# PIC32MZ0512EFF144 device description
Architecture: 32xxxx; Family: PIC32MZEF; Series: PIC32MZ
Registers are 32-bit, read-write, no defined reset value unless marked. A register's access mark holds for its fields unless they carry their own. Offsets are from the block's base; [hi:lo] are bit positions; {n}, {i} and the like mark numbered series; 'fields as' and 'values as' point back to an identical list.

## RPIN
Instances: RPIN 0x1f801404 in periph_pb1_std
0x00 INT1R
  [3:0] INT1R
0x04 INT2R
  [3:0] INT2R
0x08 INT3R
  [3:0] INT3R
0x0C INT4R
  [3:0] INT4R
{0xC+4i} T{i}CKR (i=2..9)
  [3:0] T{i}CKR
{0x30+4i} IC{i}R (i=1..9)
  [3:0] IC{i}R
0x5C OCFAR
  [3:0] OCFAR
{0x5C+8i} U{i}RXR (i=1..6)
  [3:0] U{i}RXR
{0x60+8i} U{i}CTSR (i=1..6)
  [3:0] U{i}CTSR
{0x8C+0xC*i} SDI{i}R (i=1..6)
  [3:0] SDI{i}R
{0x90+0xC*i} SS{i}R (i=1..6)
  [3:0] SS{i}R
0xDC C1RXR
  [3:0] C1RXR
0xE0 C2RXR
  [3:0] C2RXR
0xE4 REFCLKI1R
  [3:0] REFCLKI1R
0xEC REFCLKI3R
  [3:0] REFCLKI3R
0xF0 REFCLKI4R
  [3:0] REFCLKI4R

## RPOUT
Instances: RPOUT 0x1f801538 in periph_pb1_std
0x00 RPA14R
  [3:0] RPA14R
0x04 RPA15R
  [3:0] RPA15R
{0x8+4i} RPB{i}R (i=0..3)
  [3:0] RPB{i}R
{0x8+4i} RPB{i}R (i=5..10)
  [3:0] RPB{i}R
0x40 RPB14R
  [3:0] RPB14R
0x44 RPB15R
  [3:0] RPB15R
{0x48+4i} RPC{i}R (i=1..4)
  [3:0] RPC{i}R
0x7C RPC13R
  [3:0] RPC13R
0x80 RPC14R
  [3:0] RPC14R
{0x88+4i} RPD{i}R (i=0..7)
  [3:0] RPD{i}R
{0x88+4i} RPD{i}R (i=9..12)
  [3:0] RPD{i}R
0xC0 RPD14R
  [3:0] RPD14R
0xC4 RPD15R
  [3:0] RPD15R
0xD4 RPE3R
  [3:0] RPE3R
0xDC RPE5R
  [3:0] RPE5R
0xE8 RPE8R
  [3:0] RPE8R
0xEC RPE9R
  [3:0] RPE9R
{0x108+4i} RPF{i}R (i=0..5)
  [3:0] RPF{i}R
0x128 RPF8R
  [3:0] RPF8R
0x138 RPF12R
  [3:0] RPF12R
0x13C RPF13R
  [3:0] RPF13R
0x148 RPG0R
  [3:0] RPG0R
0x14C RPG1R
  [3:0] RPG1R
{0x148+4i} RPG{i}R (i=6..9)
  [3:0] RPG{i}R

## RTCC
Instances: RTCC 0x1f800c00 in periph_pb1_std
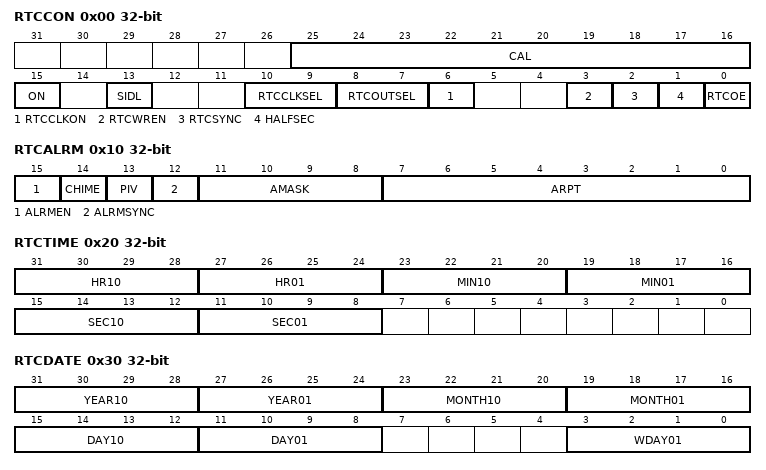
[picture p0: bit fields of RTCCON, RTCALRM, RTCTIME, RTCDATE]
0x00 RTCCON — Real-Time Clock and Calendar Control Register
  [25:16] CAL — Real-Time Clock Drift Calibration bits
    0x1ff=Maximum positive adjustment; 1=Minimum positive adjustment; 0=No adjustment; 0x3ff=Minimum negative adjustment; 0x200=Minimum negative adjustment
  [15] ON — RTCC On bit
    1=RTCC module is enabled; 0=RTCC module is disabled
  [13] SIDL — Stop in Idle Mode bit
    1=Disables RTCC operation when CPU enters Idle mode; 0=Continue normal operation when CPU enters Idle mode
  [10:9] RTCCLKSEL — RTCC Clock Select bits
    1=RTCC uses the external 32.768 kHz Secondary Oscillator (SOSC); 0=RTCC uses the internal 32 kHz oscillator (LPRC)
  [8:7] RTCOUTSEL — RTCC Output Data Select bits
    2=RTCC Clock is presented on the RTCC pin; 1=Seconds Clock is presented on the RTCC pin; 0=Alarm Pulse is presented on the RTCC pin when the alarm interrupt is triggered
  [6] RTCCLKON — RTCC Clock Enable Status bit
    1=RTCC Clock is actively running; 0=RTCC Clock is not running
  [3] RTCWREN — Real-Time Clock Value Registers Write Enable bit
    1=Real-Time Clock Value registers can be written to by the user; 0=Real-Time Clock Value registers are locked out from being written to by the user
  [2] RTCSYNC — Real-Time Clock Value Registers Read Synchronization bit
    1=Real-time clock value registers can change while reading (due to a rollover ripple that results in an invalid data read). If the register is read twice and results in the same data; 0=Real-time clock value registers can be read without concern about a rollover ripple
  [1] HALFSEC — Half-Second Status bit
    1=Second half period of a second; 0=First half period of a second
  [0] RTCOE — RTCC Output Enable bit
    1=RTCC output is enabled; 0=RTCC output is not enabled
0x10 RTCALRM — Real-Time Clock ALARM Control Register
  [15] ALRMEN — Alarm Enable bit
    1=Alarm is enabled; 0=Alarm is disabled
  [14] CHIME — Chime Enable bit
    1=Chime is enabled ARPT is allowed to rollover from 0x00 to 0xFF; 0=Chime is disabled ARPT stops once it reaches 0x00
  [13] PIV — Alarm Pulse Initial Value bit
    0=low initial value of the Alarm Pulse (When ALRMEN = 0); 1=high initial value of the Alarm Pulse (When ALRMEN = 0)
  [12] ALRMSYNC — Alarm Sync bit
    1=ARPT and ALRMEN may change as a result of a half second rollover during a read. The ARPT must be read repeatedly until the same value is read twice. This must be done since multiple bits may be changing.; 0=ARPT and ALRMEN can be read without concerns of rollover because the prescaler is more than 32 real-time clocks away from a half-second rollover
  [11:8] AMASK — Alarm Mask Configuration bits
    0=Every half-second; 1=Every second; 2=Every 10 seconds; 3=Every minute; 4=Every 10 minutes; 5=Every hour; 6=Once a day; 7=Once a week; 8=Once a month; 9=Once a year (except when configured for February 29
  [7:0] ARPT — Alarm Repeat Counter Value bits
    255=Alarm will trigger 256 times; 254=Alarm will trigger 255 times; 1=Alarm will trigger two times; 0=Alarm will trigger one time
0x20 RTCTIME — Real-Time Clock Time Value Register
  [31:28] HR10, [27:24] HR01, [23:20] MIN10, [19:16] MIN01, [15:12] SEC10, [11:8] SEC01
0x30 RTCDATE — Real-Time Clock Date Value Register
  [31:28] YEAR10, [27:24] YEAR01, [23:20] MONTH10, [19:16] MONTH01, [15:12] DAY10, [11:8] DAY01, [3:0] WDAY01
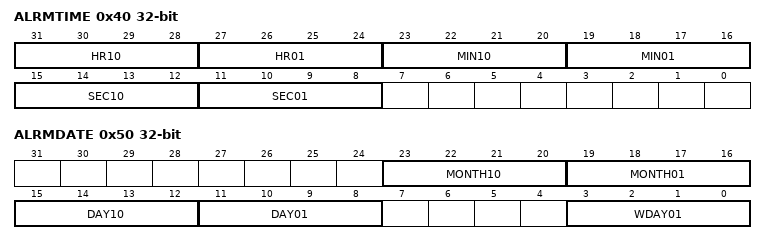
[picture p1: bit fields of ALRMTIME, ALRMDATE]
0x40 ALRMTIME — Alarm Time Value Register
  fields as RTCTIME
0x50 ALRMDATE — Alarm Date Value Register
  [23:20] MONTH10, [19:16] MONTH01, [15:12] DAY10, [11:8] DAY01, [3:0] WDAY01
